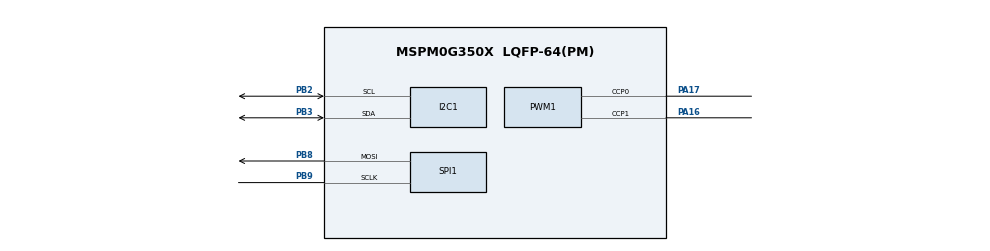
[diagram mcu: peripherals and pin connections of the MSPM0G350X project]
/**
 * @cliArgs --device "MSPM0G350X" --part "Default" --package "LQFP-64(PM)" --product "mspm0_sdk@2.04.00.06"
 * @versions {"tool":"1.23.1+4034"}
 */

/**
 * Import the modules used in this configuration.
 */
const GPIO    = scripting.addModule("/ti/driverlib/GPIO", {}, false);
const GPIO1   = GPIO.addInstance();
const GPIO2   = GPIO.addInstance();
const GPIO3   = GPIO.addInstance();
const GPIO4   = GPIO.addInstance();
const GPIO5   = GPIO.addInstance();
const GPIO6   = GPIO.addInstance();
const GPIO7   = GPIO.addInstance();
const GPIO8   = GPIO.addInstance();
const I2C     = scripting.addModule("/ti/driverlib/I2C", {}, false);
const I2C1    = I2C.addInstance();
const PWM     = scripting.addModule("/ti/driverlib/PWM", {}, false);
const PWM1    = PWM.addInstance();
const SPI     = scripting.addModule("/ti/driverlib/SPI", {}, false);
const SPI1    = SPI.addInstance();
const SYSCTL  = scripting.addModule("/ti/driverlib/SYSCTL");
const SYSTICK = scripting.addModule("/ti/driverlib/SYSTICK");
const TIMER   = scripting.addModule("/ti/driverlib/TIMER", {}, false);
const TIMER1  = TIMER.addInstance();

/**
 * Write custom configuration values to the imported modules.
 */
const divider9       = system.clockTree["UDIV"];
divider9.divideValue = 2;

const mux4       = system.clockTree["EXHFMUX"];
mux4.inputSelect = "EXHFMUX_XTAL";

const mux8       = system.clockTree["HSCLKMUX"];
mux8.inputSelect = "HSCLKMUX_SYSPLL2X";

const mux12       = system.clockTree["SYSPLLMUX"];
mux12.inputSelect = "zSYSPLLMUX_HFCLK";

const pinFunction4        = system.clockTree["HFXT"];
pinFunction4.inputFreq    = 40;
pinFunction4.HFXTStartup  = 20;
pinFunction4.enable       = true;
pinFunction4.HFCLKMonitor = true;

GPIO1.port                           = "PORTA";
GPIO1.$name                          = "TB6612";
GPIO1.associatedPins.create(4);
GPIO1.associatedPins[0].$name        = "AIN1";
GPIO1.associatedPins[0].assignedPin  = "14";
GPIO1.associatedPins[0].initialValue = "SET";
GPIO1.associatedPins[1].$name        = "AIN2";
GPIO1.associatedPins[1].assignedPin  = "15";
GPIO1.associatedPins[1].initialValue = "SET";
GPIO1.associatedPins[2].$name        = "BIN1";
GPIO1.associatedPins[2].assignedPin  = "12";
GPIO1.associatedPins[2].initialValue = "SET";
GPIO1.associatedPins[3].$name        = "BIN2";
GPIO1.associatedPins[3].assignedPin  = "13";
GPIO1.associatedPins[3].initialValue = "SET";

const Board = scripting.addModule("/ti/driverlib/Board", {}, false);

GPIO2.$name                               = "L_ENCODER";
GPIO2.port                                = "PORTB";
GPIO2.associatedPins.create(2);
GPIO2.associatedPins[0].direction         = "INPUT";
GPIO2.associatedPins[0].interruptEn       = true;
GPIO2.associatedPins[0].interruptPriority = "0";
GPIO2.associatedPins[0].polarity          = "RISE";
GPIO2.associatedPins[0].assignedPin       = "0";
GPIO2.associatedPins[0].$name             = "LENA";
GPIO2.associatedPins[1].assignedPin       = "1";
GPIO2.associatedPins[1].direction         = "INPUT";
GPIO2.associatedPins[1].interruptEn       = true;
GPIO2.associatedPins[1].interruptPriority = "0";
GPIO2.associatedPins[1].polarity          = "RISE";
GPIO2.associatedPins[1].$name             = "LENB";

GPIO3.$name                         = "TFT";
GPIO3.port                          = "PORTB";
GPIO3.associatedPins.create(4);
GPIO3.associatedPins[0].$name       = "RES";
GPIO3.associatedPins[0].assignedPin = "10";
GPIO3.associatedPins[1].$name       = "DC";
GPIO3.associatedPins[1].assignedPin = "11";
GPIO3.associatedPins[2].$name       = "CS";
GPIO3.associatedPins[2].assignedPin = "14";
GPIO3.associatedPins[3].$name       = "BLK";
GPIO3.associatedPins[3].assignedPin = "26";

GPIO4.$name                         = "IIC_Software";
GPIO4.port                          = "PORTA";
GPIO4.associatedPins.create(2);
GPIO4.associatedPins[0].$name       = "SCL";
GPIO4.associatedPins[0].ioStructure = "OD";
GPIO4.associatedPins[0].assignedPin = "1";
GPIO4.associatedPins[1].$name       = "SDA";
GPIO4.associatedPins[1].ioStructure = "OD";
GPIO4.associatedPins[1].assignedPin = "0";

GPIO5.$name                               = "R_ENCODER";
GPIO5.port                                = "PORTA";
GPIO5.associatedPins.create(2);
GPIO5.associatedPins[0].direction         = "INPUT";
GPIO5.associatedPins[0].assignedPin       = "8";
GPIO5.associatedPins[0].interruptEn       = true;
GPIO5.associatedPins[0].interruptPriority = "0";
GPIO5.associatedPins[0].polarity          = "RISE";
GPIO5.associatedPins[0].$name             = "RENA";
GPIO5.associatedPins[1].assignedPin       = "9";
GPIO5.associatedPins[1].direction         = "INPUT";
GPIO5.associatedPins[1].interruptEn       = true;
GPIO5.associatedPins[1].interruptPriority = "0";
GPIO5.associatedPins[1].polarity          = "RISE";
GPIO5.associatedPins[1].$name             = "RENB";

GPIO6.$name                              = "KEY";
GPIO6.port                               = "PORTA";
GPIO6.associatedPins.create(4);
GPIO6.associatedPins[0].$name            = "K1";
GPIO6.associatedPins[0].direction        = "INPUT";
GPIO6.associatedPins[0].assignedPin      = "24";
GPIO6.associatedPins[0].internalResistor = "PULL_UP";
GPIO6.associatedPins[0].polarity         = "RISE";
GPIO6.associatedPins[1].$name            = "K2";
GPIO6.associatedPins[1].direction        = "INPUT";
GPIO6.associatedPins[1].internalResistor = "PULL_UP";
GPIO6.associatedPins[1].assignedPin      = "25";
GPIO6.associatedPins[2].$name            = "K3";
GPIO6.associatedPins[2].direction        = "INPUT";
GPIO6.associatedPins[2].internalResistor = "PULL_UP";
GPIO6.associatedPins[2].polarity         = "RISE";
GPIO6.associatedPins[2].assignedPin      = "26";
GPIO6.associatedPins[3].$name            = "K4";
GPIO6.associatedPins[3].direction        = "INPUT";
GPIO6.associatedPins[3].internalResistor = "PULL_UP";
GPIO6.associatedPins[3].assignedPin      = "27";

GPIO7.$name                              = "LED";
GPIO7.port                               = "PORTB";
GPIO7.associatedPins[0].$name            = "PIN_22";
GPIO7.associatedPins[0].internalResistor = "PULL_DOWN";
GPIO7.associatedPins[0].assignedPin      = "22";

GPIO8.$name                              = "BEE";
GPIO8.port                               = "PORTB";
GPIO8.associatedPins[0].$name            = "PIN_23";
GPIO8.associatedPins[0].assignedPin      = "23";
GPIO8.associatedPins[0].internalResistor = "PULL_UP";

I2C1.$name                             = "I2C_eightways";
I2C1.basicEnableController             = true;
I2C1.basicControllerStandardBusSpeed   = "Fast";
I2C1.peripheral.sdaPin.$assign         = "PB3";
I2C1.peripheral.sclPin.$assign         = "PB2";
I2C1.sdaPinConfig.hideOutputInversion  = scripting.forceWrite(false);
I2C1.sdaPinConfig.onlyInternalResistor = scripting.forceWrite(false);
I2C1.sdaPinConfig.passedPeripheralType = scripting.forceWrite("Digital");
I2C1.sdaPinConfig.$name                = "ti_driverlib_gpio_GPIOPinGeneric2";
I2C1.sclPinConfig.hideOutputInversion  = scripting.forceWrite(false);
I2C1.sclPinConfig.onlyInternalResistor = scripting.forceWrite(false);
I2C1.sclPinConfig.passedPeripheralType = scripting.forceWrite("Digital");
I2C1.sclPinConfig.$name                = "ti_driverlib_gpio_GPIOPinGeneric3";

PWM1.$name                      = "PWM_0";
PWM1.timerStartTimer            = true;
PWM1.clockDivider               = 8;
PWM1.peripheral.$assign         = "TIMA1";
PWM1.peripheral.ccp0Pin.$assign = "PA17";
PWM1.peripheral.ccp1Pin.$assign = "PA16";
PWM1.PWM_CHANNEL_0.$name        = "ti_driverlib_pwm_PWMTimerCC0";
PWM1.PWM_CHANNEL_0.invert       = true;
PWM1.PWM_CHANNEL_1.$name        = "ti_driverlib_pwm_PWMTimerCC1";
PWM1.PWM_CHANNEL_1.invert       = true;
PWM1.ccp0PinConfig.$name        = "ti_driverlib_gpio_GPIOPinGeneric0";
PWM1.ccp1PinConfig.$name        = "ti_driverlib_gpio_GPIOPinGeneric1";

SPI1.$name                              = "TFT_SPI";
SPI1.frameFormat                        = "MOTO3";
SPI1.direction                          = "PICO";
SPI1.sclkPinConfig.$name                = "ti_driverlib_gpio_GPIOPinGeneric4";
SPI1.sclkPinConfig.direction            = scripting.forceWrite("OUTPUT");
SPI1.sclkPinConfig.onlyInternalResistor = scripting.forceWrite(false);
SPI1.sclkPinConfig.passedPeripheralType = scripting.forceWrite("Digital");
SPI1.mosiPinConfig.$name                = "ti_driverlib_gpio_GPIOPinGeneric5";
SPI1.mosiPinConfig.direction            = scripting.forceWrite("OUTPUT");
SPI1.mosiPinConfig.hideOutputInversion  = scripting.forceWrite(false);
SPI1.mosiPinConfig.onlyInternalResistor = scripting.forceWrite(false);
SPI1.mosiPinConfig.passedPeripheralType = scripting.forceWrite("Digital");
SPI1.peripheral.$assign                 = "SPI1";
SPI1.peripheral.sclkPin.$assign         = "PB9";
SPI1.peripheral.mosiPin.$assign         = "PB8";

SYSCTL.forceDefaultClkConfig = true;
SYSCTL.clockTreeEn           = true;
SYSCTL.validateClkStatus     = true;

SYSTICK.periodEnable  = true;
SYSTICK.systickEnable = true;
SYSTICK.period        = 80;

TIMER1.$name             = "TIMER_TICK";
TIMER1.timerClkDiv       = 8;
TIMER1.timerClkPrescale  = 10;
TIMER1.timerMode         = "PERIODIC";
TIMER1.timerPeriod       = "20ms";
TIMER1.timerStartTimer   = true;
TIMER1.interrupts        = ["ZERO"];
TIMER1.interruptPriority = "3";

/**
 * Pinmux solution for unlocked pins/peripherals. This ensures that minor changes to the automatic solver in a future
 * version of the tool will not impact the pinmux you originally saw.  These lines can be completely deleted in order to
 * re-solve from scratch.
 */
pinFunction4.peripheral.$suggestSolution           = "SYSCTL";
pinFunction4.peripheral.hfxInPin.$suggestSolution  = "PA5";
pinFunction4.peripheral.hfxOutPin.$suggestSolution = "PA6";
GPIO1.associatedPins[0].pin.$suggestSolution       = "PA14";
GPIO1.associatedPins[1].pin.$suggestSolution       = "PA15";
GPIO1.associatedPins[2].pin.$suggestSolution       = "PA12";
GPIO1.associatedPins[3].pin.$suggestSolution       = "PA13";
Board.peripheral.$suggestSolution                  = "DEBUGSS";
Board.peripheral.swclkPin.$suggestSolution         = "PA20";
Board.peripheral.swdioPin.$suggestSolution         = "PA19";
GPIO2.associatedPins[0].pin.$suggestSolution       = "PB0";
GPIO2.associatedPins[1].pin.$suggestSolution       = "PB1";
GPIO3.associatedPins[0].pin.$suggestSolution       = "PB10";
GPIO3.associatedPins[1].pin.$suggestSolution       = "PB11";
GPIO3.associatedPins[2].pin.$suggestSolution       = "PB14";
GPIO3.associatedPins[3].pin.$suggestSolution       = "PB26";
GPIO4.associatedPins[0].pin.$suggestSolution       = "PA1";
GPIO4.associatedPins[1].pin.$suggestSolution       = "PA0";
GPIO5.associatedPins[0].pin.$suggestSolution       = "PA8";
GPIO5.associatedPins[1].pin.$suggestSolution       = "PA9";
GPIO6.associatedPins[0].pin.$suggestSolution       = "PA24";
GPIO6.associatedPins[1].pin.$suggestSolution       = "PA25";
GPIO6.associatedPins[2].pin.$suggestSolution       = "PA26";
GPIO6.associatedPins[3].pin.$suggestSolution       = "PA27";
GPIO7.associatedPins[0].pin.$suggestSolution       = "PB22";
GPIO8.associatedPins[0].pin.$suggestSolution       = "PB23";
I2C1.peripheral.$suggestSolution                   = "I2C1";
TIMER1.peripheral.$suggestSolution                 = "TIMA0";
